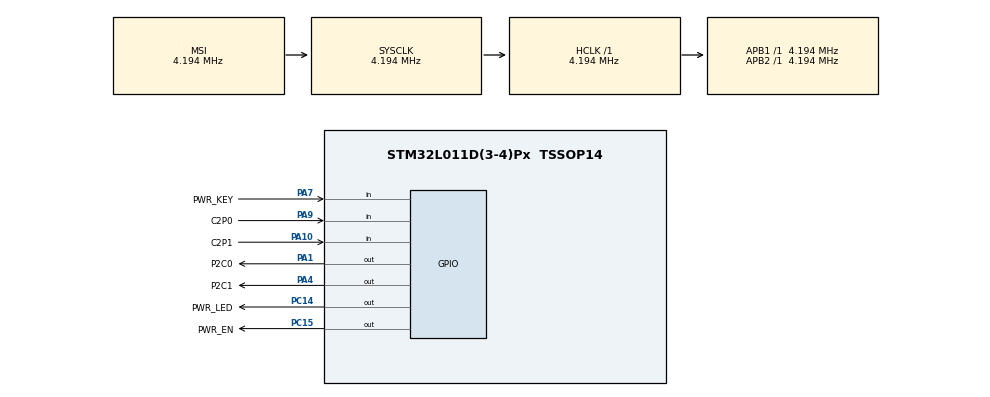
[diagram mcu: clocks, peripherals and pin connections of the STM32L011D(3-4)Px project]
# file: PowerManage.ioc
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Mcu.Family=STM32L0
Mcu.Name=STM32L011D(3-4)Px
Mcu.Package=TSSOP14
PA0-CK_IN.Mode=SYS_WakeUp0
PA0-CK_IN.Signal=SYS_WKUP1
PA1.GPIO_Label=P2C0
PA1.GPIO_PuPd=GPIO_PULLDOWN
PA1.GPIO_Speed=GPIO_SPEED_FREQ_LOW
PA1.Signal=GPIO_Output
PA10.GPIO_Label=C2P1
PA10.Signal=GPIO_Input
PA13.Mode=Serial_Wire
PA13.Signal=SYS_SWDIO
PA14.Mode=Serial_Wire
PA14.Signal=SYS_SWCLK
PA4.GPIO_Label=P2C1
PA4.Signal=GPIO_Output
PA7.GPIO_Label=PWR_KEY
PA7.Signal=GPIO_Input
PA9.GPIO_Label=C2P0
PA9.Signal=GPIO_Input
PC14-OSC32_IN.GPIO_Label=PWR_LED
PC14-OSC32_IN.GPIO_PuPd=GPIO_PULLUP
PC14-OSC32_IN.Signal=GPIO_Output
PC15-OSC32_OUT.GPIO_Label=PWR_EN
PC15-OSC32_OUT.GPIO_ModeDefaultOutputPP=GPIO_MODE_OUTPUT_OD
PC15-OSC32_OUT.GPIO_PuPd=GPIO_PULLUP
PC15-OSC32_OUT.PinState=GPIO_PIN_SET
PC15-OSC32_OUT.Signal=GPIO_Output
ProjectManager.HeapSize=0x200
ProjectManager.StackSize=0x400
ProjectManager.TargetToolchain=MDK-ARM V5.32
RCC.AHBFreq_Value=4194000
RCC.APB1Freq_Value=4194000
RCC.APB1TimFreq_Value=4194000
RCC.APB2Freq_Value=4194000
RCC.APB2TimFreq_Value=4194000
RCC.HCLKFreq_Value=4194000
RCC.HSE_VALUE=8000000
RCC.HSI16_VALUE=16000000
RCC.HSI_VALUE=16000000
RCC.LSE_VALUE=32768
RCC.MSIClockRange=RCC_MSIRANGE_6
RCC.MSI_VALUE=4194000
RCC.SYSCLKFreq_VALUE=4194000
RCC.VCOOutputFreq_Value=48000000
board=custom

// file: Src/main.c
/* USER CODE BEGIN Header */
/**
  ******************************************************************************
  * @file           : main.c
  * @brief          : Main program body
  ******************************************************************************
  * @attention
  *
  * Copyright (c) 2025 STMicroelectronics.
  * All rights reserved.
  *
  * This software is licensed under terms that can be found in the LICENSE file
  * in the root directory of this software component.
  * If no LICENSE file comes with this software, it is provided AS-IS.
  *
  ******************************************************************************
  */
/* USER CODE END Header */
#include "main.h"
#include "gpio.h"
#include "stm32l0xx_hal_gpio.h"

void SystemClock_Config(void);

int main(void)
{

  /* USER CODE BEGIN 1 */
	volatile uint8_t a = 0;
  HAL_GPIO_WritePin(PWR_LED_GPIO_Port, PWR_LED_Pin, GPIO_PIN_SET);
  /* USER CODE END 1 */

  /* MCU Configuration--------------------------------------------------------*/

  /* Reset of all peripherals, Initializes the Flash interface and the Systick. */
  HAL_Init();

  /* Configure the system clock */
  SystemClock_Config();

  /* Initialize all configured peripherals */
  MX_GPIO_Init();

  /* Infinite loop */
  while (1)
  {

    /* USER CODE BEGIN 3 */
    if (a == 1)
    {
      HAL_GPIO_WritePin(PWR_EN_GPIO_Port, PWR_EN_Pin, GPIO_PIN_RESET);
    }
    else{
      HAL_GPIO_WritePin(PWR_EN_GPIO_Port, PWR_EN_Pin, GPIO_PIN_SET);
    }

  }
  /* USER CODE END 3 */
}

void SystemClock_Config(void)
{
  RCC_OscInitTypeDef RCC_OscInitStruct = {0};
  RCC_ClkInitTypeDef RCC_ClkInitStruct = {0};

  /** Configure the main internal regulator output voltage
  */
  __HAL_PWR_VOLTAGESCALING_CONFIG(PWR_REGULATOR_VOLTAGE_SCALE1);

  /** Initializes the RCC Oscillators according to the specified parameters
  * in the RCC_OscInitTypeDef structure.
  */
  RCC_OscInitStruct.OscillatorType = RCC_OSCILLATORTYPE_MSI;
  RCC_OscInitStruct.MSIState = RCC_MSI_ON;
  RCC_OscInitStruct.MSICalibrationValue = 0;
  RCC_OscInitStruct.MSIClockRange = RCC_MSIRANGE_6;
  RCC_OscInitStruct.PLL.PLLState = RCC_PLL_NONE;
  if (HAL_RCC_OscConfig(&RCC_OscInitStruct) != HAL_OK)
  {
    Error_Handler();
  }

  /** Initializes the CPU, AHB and APB buses clocks
  */
  RCC_ClkInitStruct.ClockType = RCC_CLOCKTYPE_HCLK|RCC_CLOCKTYPE_SYSCLK
                              |RCC_CLOCKTYPE_PCLK1|RCC_CLOCKTYPE_PCLK2;
  RCC_ClkInitStruct.SYSCLKSource = RCC_SYSCLKSOURCE_MSI;
  RCC_ClkInitStruct.AHBCLKDivider = RCC_SYSCLK_DIV1;
  RCC_ClkInitStruct.APB1CLKDivider = RCC_HCLK_DIV1;
  RCC_ClkInitStruct.APB2CLKDivider = RCC_HCLK_DIV1;

  if (HAL_RCC_ClockConfig(&RCC_ClkInitStruct, FLASH_LATENCY_0) != HAL_OK)
  {
    Error_Handler();
  }
}

void Error_Handler(void)
{
  __disable_irq();
  while (1)
  {
  }
}
